AUTOSAR XML (schema 00051)
standard types defined: boolean, sint16, uint16, uint32, uint8
package /SharedElements/PortInterfaces/ClientServer
  client server interface InProc_OBCSt_SR
    operation OBC00S  # Turn switch sensor position [left, off, right]
      arg Argument: type=sint16, direction=IN, server-argument-impl-policy=USE-ARGUMENT-TYPE
    operation OBC01S  # Turn switch sensor position [left, off, right]
      arg Argument: type=uint8, direction=OUT, server-argument-impl-policy=USE-ARGUMENT-TYPE
package /SharedElements/PortInterfaces/ModeSwitch
  mode declaration group ModeDeclarationGroup: category=EXPLICIT_ORDER, initial-mode=ModeDeclaration, on-transition-value=4
    4 x mode:
      ModeDeclaration: value=1
      ModeDeclaration1: value=3
      ModeDeclaration2: value=0
      ModeDeclaration3: value=2
  mode switch interface ModeSwitchInterface
    mode group ModeGroup: type=ModeDeclarationGroup
package /SharedElements/PortInterfaces/NvData
  nv data interface InProc_OBCErPrmntActvDschrg_SR
    nv-datas:
      4 x data:
        OBC00EPAD  # Turn switch sensor position [left, off, right]
        OBC01EPAD  # Turn switch sensor position [left, off, right]
        OBC10EPAD  # Turn switch sensor position [left, off, right]
        OBC11EPAD  # Turn switch sensor position [left, off, right]
  nv data interface NV_BCBStatDrsn_NVD
    nv-datas:
      data BCBStatDrsn_NvData  # Turn switch sensor position [left, off, right]
package /SharedElements/PortInterfaces/Parameter
  parameter interface GC_ActvDshgStrtTm_PI
    parameter data prototype ADST  # Turn switch sensor position [left, off, right]
package /SharedElements/PortInterfaces/SenderReceiver
  sender receiver interface WPD_EOBCIout_SR: invalidation-policy{data-element=EOBCIo, handle-invalid=DONT-INVALIDATE}
    data EOBCIo  # Turn switch sensor position [left, off, right]
package /SharedElements/PortInterfaces/Trigger
  trigger interface TriggerInterface
package /SharedElements/SWCImpl
  swc implementation SwcImplementation: programming-language=C, sw-version=1.0.0.0, behavior=IB_MdMgmt
    resource consumption ResourceConsumption
package /SharedElements/SwAddrMethods
  sw addr method SwAddrMethod
package /SwComponentTypes/ApplSWC
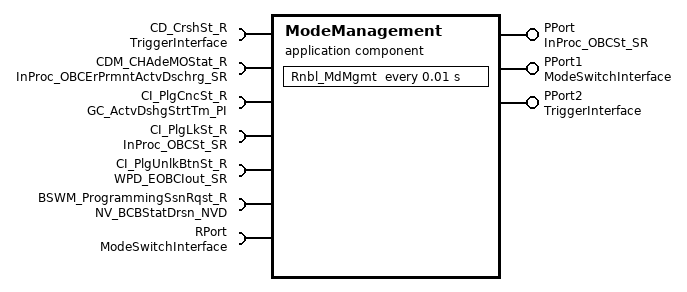
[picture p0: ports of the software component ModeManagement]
  application sw component type ModeManagement
    6 x require port:
      CD_CrshSt_R: required-interface=TriggerInterface
      CDM_CHAdeMOStat_R: required-interface=InProc_OBCErPrmntActvDschrg_SR
      CI_PlgCncSt_R: required-interface=GC_ActvDshgStrtTm_PI
      CI_PlgLkSt_R: required-interface=InProc_OBCSt_SR
      CI_PlgUnlkBtnSt_R: required-interface=WPD_EOBCIout_SR
      BSWM_ProgrammingSsnRqst_R: required-interface=NV_BCBStatDrsn_NVD
    provide port PPort: provided-interface=InProc_OBCSt_SR
    provide port PPort1: provided-interface=ModeSwitchInterface
    require port RPort: required-interface=ModeSwitchInterface
    provide port PPort2: provided-interface=TriggerInterface
    behavior IB_MdMgmt: handle-termination-and-restart=NO-SUPPORT
      constant-memorys:
        parameter data prototype ConstantMemory: sw-calibration-access=READ-WRITE, type=uint8
      static-memorys:
        data StaticMemory: type=uint32
      ar-typed-per-instance-memorys:
        data ArTypedPerInstanceMemory: type=uint16
      init event MdMgmt_InitEvent: start-on-event=MdMgmt_Init
      init event MdMgmt_InitEvent1: start-on-event=MdMgmt_Init1
      timing event MdMgmt10ms: start-on-event=Rnbl_MdMgmt, period=0.01
      asynchronous server call returns event AsynchronousServerCallReturnsEvent: start-on-event=Runnable1
      background event BackgroundEvent
      data receive error event DataReceiveErrorEvent
      data received event DataReceivedEvent
      data send completed event DataSendCompletedEvent
      data write completed event DataWriteCompletedEvent
      external trigger occurred event ExternalTriggerOccurredEvent: start-on-event=Runnable4
      internal trigger occurred event InternalTriggerOccurredEvent: start-on-event=Runnable4, event-source=InternalTriggeringPoint
      mode switched ack event ModeSwitchedAckEvent: start-on-event=Runnable3, event-source=Runnable2/MSP_PPort1_ModeGroup
      operation invoked event OperationInvokedEvent: start-on-event=Runnable, operation=PPort.OBC00S
      swc mode manager error event SwcModeManagerErrorEvent
      swc mode switch event SwcModeSwitchEvent: start-on-event=Runnable2, activation=ON-TRANSITION, mode=[RPort.ModeGroup.ModeDeclaration3, RPort.ModeGroup.ModeDeclaration]
      transformer hard error event TransformerHardErrorEvent
      explicit-inter-runnable-variables:
        data ExplicitInterRunnableVariable
      implicit-inter-runnable-variables:
        data ImplicitInterRunnableVariable
      per-instance-parameters:
        parameter data prototype PerInstanceParameter: sw-calibration-access=READ-WRITE, type=uint32
      port-api-options:
        enable-take-address=true, indirect-api=false, port=BSWM_ProgrammingSsnRqst_R
        enable-take-address=false, indirect-api=false, port=CDM_CHAdeMOStat_R
        enable-take-address=false, indirect-api=false, port=CD_CrshSt_R
        enable-take-address=false, indirect-api=false, port=CI_PlgCncSt_R
        {enable-take-address=true, indirect-api=true, port-arg-values=[{value=14, value-type=uint32}, {value=Value:1, value-type=boolean}], port=CI_PlgLkSt_R}
        enable-take-address=false, indirect-api=false, port=CI_PlgUnlkBtnSt_R
      8 x runnable:
        MdMgmt_Init
        MdMgmt_Init1
        Rnbl_MdMgmt
          data-read-access:
            access DRA_BSWM_ProgrammingSsnRqst_R_BCBStatDrsn_NvData: accessed-variable=BSWM_ProgrammingSsnRqst_R.BCBStatDrsn_NvData
            access DRA_CDM_CHAdeMOStat_R_OBC01EPAD: accessed-variable=CDM_CHAdeMOStat_R.OBC01EPAD
            access DRA_CDM_CHAdeMOStat_R_OBC11EPAD: accessed-variable=CDM_CHAdeMOStat_R.OBC11EPAD
          data-receive-point-by-arguments:
            access DRP_CDM_CHAdeMOStat_R_OBC00EPAD: accessed-variable=CDM_CHAdeMOStat_R.OBC00EPAD
            access DRP_CDM_CHAdeMOStat_R_OBC01EPAD: accessed-variable=CDM_CHAdeMOStat_R.OBC01EPAD
            access DRP_CI_PlgUnlkBtnSt_R_EOBCIo: accessed-variable=CI_PlgUnlkBtnSt_R.EOBCIo
          data-receive-point-by-values:
            access DRPV_CDM_CHAdeMOStat_R_OBC10EPAD: accessed-variable=CDM_CHAdeMOStat_R.OBC10EPAD
            access DRPV_CDM_CHAdeMOStat_R_OBC11EPAD: accessed-variable=CDM_CHAdeMOStat_R.OBC11EPAD
            access DRPV_CI_PlgUnlkBtnSt_R_EOBCIo: accessed-variable=CI_PlgUnlkBtnSt_R.EOBCIo
          mode-access-point mode-group=PPort1.ModeGroup:
            ident MAP_PPort1_ModeGroup
          mode-access-point mode-group=RPort.ModeGroup:
            ident MAP_RPort_ModeGroup
          mode switch point MSP_PPort1_ModeGroup: mode-group=PPort1.ModeGroup
          4 x parameter access:
            ParameterAccess: accessed-parameter=ConstantMemory
            PICPVA_PerInstanceParameter: accessed-parameter=PerInstanceParameter
            CPA_CI_PlgCncSt_R_ADST: accessed-parameter=CI_PlgCncSt_R.ADST
            SCPVA_SharedParameter: accessed-parameter=SharedParameter
          read-local-variables:
            access IRVRA_ExplicitInterRunnableVariable: accessed-variable=ExplicitInterRunnableVariable
          sync call SSCP_CI_PlgLkSt_R_OBC01S: operation=CI_PlgLkSt_R.OBC01S, timeout=0
          wait point WaitPoint
          written-local-variables:
            access IRVWA_ImplicitInterRunnableVariable: accessed-variable=ImplicitInterRunnableVariable
        Runnable: runnable-entity-argument=symbol=Argument, symbol=ModeManagement_Runnable
          internal triggering point InternalTriggeringPoint
          sync call SSCP_CI_PlgLkSt_R_OBC00S: operation=CI_PlgLkSt_R.OBC00S, timeout=0
          sync call SSCP_CI_PlgLkSt_R_OBC01S: operation=CI_PlgLkSt_R.OBC01S, timeout=0
          wait point WaitPoint
        Runnable1: symbol=ModeManagement_Runnable1
        Runnable2: sw-addr-method=SwAddrMethod, symbol=ModeManagement_Runnable2
          mode-access-point mode-group=PPort1.ModeGroup:
            ident MAP_PPort1_ModeGroup
          mode-access-point mode-group=RPort.ModeGroup:
            ident MAP_RPort_ModeGroup
          mode switch point MSP_PPort1_ModeGroup: mode-group=PPort1.ModeGroup
        Runnable3: symbol=ModeManagement_Runnable3
          mode-access-point mode-group=PPort1.ModeGroup:
            ident MAP_PPort1_ModeGroup
          mode-access-point mode-group=RPort.ModeGroup:
            ident MAP_RPort_ModeGroup
          mode switch point MSP_PPort1_ModeGroup: mode-group=PPort1.ModeGroup
        Runnable4: symbol=ModeManagement_Runnable4
      swc service dependency ServiceDependency
        service-needs:
          nv block needs NvBlockNeeds
      shared-parameters:
        parameter data prototype SharedParameter: sw-calibration-access=READ-WRITE, type=uint16
